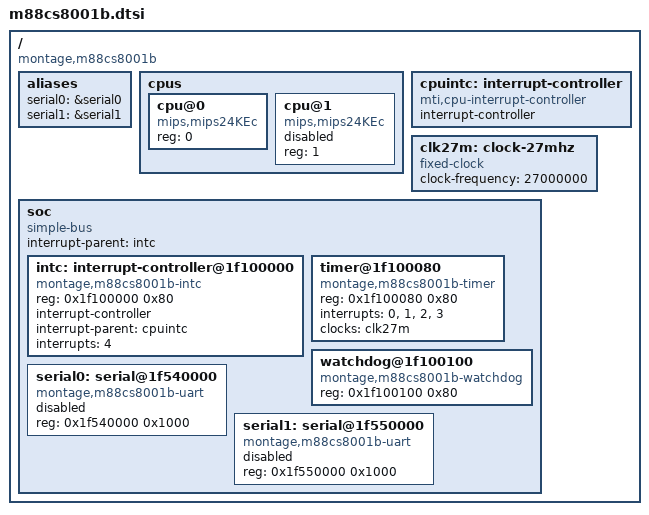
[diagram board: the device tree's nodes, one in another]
// SPDX-License-Identifier: GPL-2.0

/ {
	compatible = "montage,m88cs8001b";
	#address-cells = <1>;
	#size-cells = <1>;

	aliases {
		serial0 = &serial0;
		serial1 = &serial1;
	};

	cpus {
		#address-cells = <1>;
		#size-cells = <0>;

		cpu@0 {
			compatible = "mips,mips24KEc";
			device_type = "cpu";
			reg = <0>;
		};

		cpu@1 {
			compatible = "mips,mips24KEc";
			device_type = "cpu";
			reg = <1>;

			// SMP is not yet supported
			status = "disabled";
		};
	};

	cpuintc: interrupt-controller {
		#address-cells = <0>;
		#interrupt-cells = <1>;
		interrupt-controller;
		compatible = "mti,cpu-interrupt-controller";
	};

	clk27m: clock-27mhz {
		/* 27 MHz dummy clock */
		compatible = "fixed-clock";
		clock-frequency = <27000000>;
		#clock-cells = <0>;
	};

	soc {
		compatible = "simple-bus";
		#address-cells = <1>;
		#size-cells = <1>;
		ranges;
		interrupt-parent = <&intc>;

		intc: interrupt-controller@1f100000 {
			compatible = "montage,m88cs8001b-intc";
			reg = <0x1f100000 0x80>;
			interrupt-controller;
			#interrupt-cells = <1>;
			interrupt-parent = <&cpuintc>;
			interrupts = <4>;
		};

		timer@1f100080 {
			compatible = "montage,m88cs8001b-timer";
			reg = <0x1f100080 0x80>;
			interrupts = <0>, <1>, <2>, <3>;
			clocks = <&clk27m>;
		};

		watchdog@1f100100 {
			compatible = "montage,m88cs8001b-watchdog";
			reg = <0x1f100100 0x80>;
		};

		serial0: serial@1f540000 {
			compatible = "montage,m88cs8001b-uart";
			reg = <0x1f540000 0x1000>;
			status = "disabled";
		};

		serial1: serial@1f550000 {
			compatible = "montage,m88cs8001b-uart";
			reg = <0x1f550000 0x1000>;
			status = "disabled";
		};
	};
};
